# pocket register map
Vendor: litex
Registers are 32-bit, read-write, reset 0x0 unless marked. A register's access mark holds for its fields unless they carry their own. Offsets are from the block's base; [hi:lo] are bit positions; {n}, {i} and the like mark numbered series; 'fields as' and 'values as' point back to an identical list.

## APF_INPUT
Base 0xF0001000
0x00 CONT1_KEY — Controller 1 inputs. See docs.
0x04 CONT2_KEY — Controller 2 inputs. See docs.
0x08 CONT3_KEY — Controller 3 inputs. See docs.
0x0C CONT4_KEY — Controller 4 inputs. See docs.
{0xC+4i} CONT{i}_JOY (i=1..4) — Controller {i} joystick values. See docs.
{0x1C+4i} CONT{i}_TRIG (i=1..4) — Controller {i} trigger values. Values are binary on Pocket (`0 and 0xFFFF`), and analog on controllers with analog triggers. See docs.

## APF_INTERACT
Base 0xF0001800
0x00 INTERACT0 — Interact.json entry 0.
0x04 INTERACT_CHANGED0 — When 1, indicates the interact.json entry 0 has been updated.
  [0] interact_changed0
0x08 INTERACT1 — Interact.json entry 1.
0x0C INTERACT_CHANGED1 — When 1, indicates the interact.json entry 1 has been updated.
  [0] interact_changed1

## APF_VIDEO
Base 0xF0002000
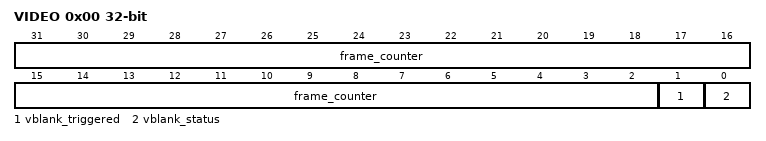
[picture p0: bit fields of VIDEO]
0x00 VIDEO
  [31:2] frame_counter — Counts the number of frames displayed since startup. Comparing this value to a previous value can be used to track frame changes. A frame change is considered to occur at the start of vblank.
  [1] vblank_triggered — Indicates when vblank occurs. Becomes 1 at vblank, and is set to 0 whenever read. If you read 1, vblank has started between your two reads.
  [0] vblank_status — 1 when in vblank, 0 otherwise.

## CTRL
Base 0xF0002800
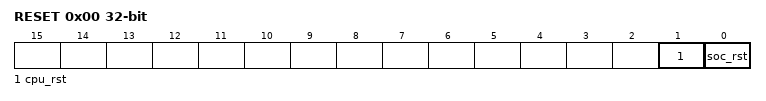
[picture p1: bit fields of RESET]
0x00 RESET
  [1] cpu_rst — Write `1` to this register to reset the CPU(s) of the SoC (Hold Reset)
  [0] soc_rst — Write `1` to this register to reset the full SoC (Pulse Reset)
0x04 SCRATCH reset 0x12345678 — Use this register as a scratch space to verify that software read/write accesses to the Wishbone/CSR bus are working correctly. The initial reset value of 0x1234578 can be used to verify endianness.
0x08 BUS_ERRORS — Total number of Wishbone bus errors (timeouts) since start.

## IDENTIFIER_MEM
Base 0xF0003000
0x00 IDENTIFIER_MEM — 8 x 47-bit memory
  [7:0] identifier_mem

## MAILBOX
Base 0xF0003800
0x00 GAME_MSG — Message word from game CPU to geometry CPU.
0x04 GAME_KICK
  [0] game_kick
0x08 GEOM_ACK
  [0] geom_ack
0x0C GEOM_MSG — Message word from geometry CPU to game CPU.
0x10 GEOM_KICK
  [0] geom_kick
0x14 GAME_ACK
  [0] game_ack
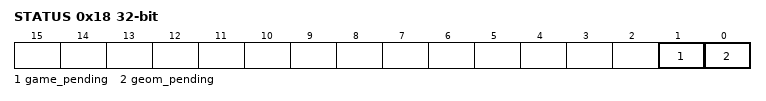
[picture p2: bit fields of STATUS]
0x18 STATUS
  [1] game_pending — Doorbell pending towards the game CPU.
  [0] geom_pending — Doorbell pending towards the geometry CPU.

## MRDP
Base 0xF0004000
0x00 CMD_DATA — Push one command word. Poll cmd_status.level first: a write to a full FIFO is lost (and counted in cmd_dropped).
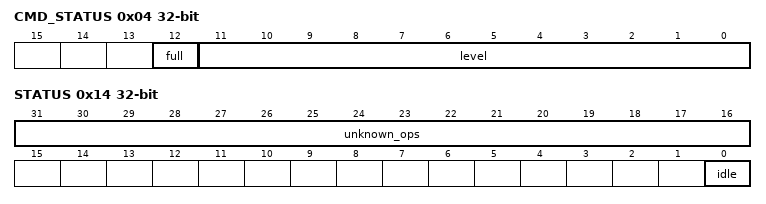
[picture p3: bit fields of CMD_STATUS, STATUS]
0x04 CMD_STATUS
  [12] full — Command FIFO full: a write now would be lost.
  [11:0] level — Command FIFO fill level.
0x08 CMD_DROPPED — Command words written while the FIFO was full (lost).
  [15:0] cmd_dropped
0x0C SYNC_COUNT — SYNC FULLs completed: every write before them is in DRAM.
0x10 LOAD_COUNT — LOAD TILEs completed (their staging memory is free again).
0x14 STATUS
  [31:16] unknown_ops — Unknown opcodes skipped.
  [0] idle — No command in progress, nothing queued, no write pending.

## SDRAM
Base 0xF0004800
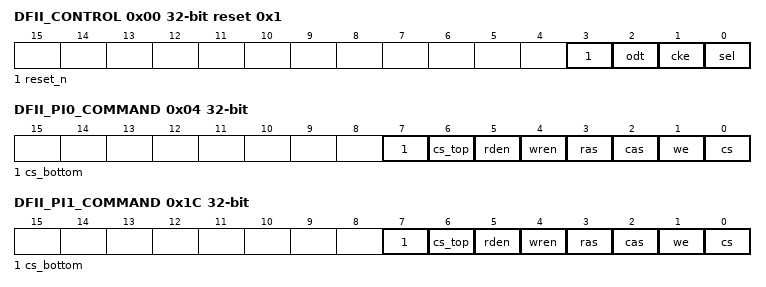
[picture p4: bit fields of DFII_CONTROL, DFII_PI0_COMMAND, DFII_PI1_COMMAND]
0x00 DFII_CONTROL reset 0x1 — Control DFI signals common to all phases
  [3] reset_n — DFI clock reset bus
  [2] odt — DFI on-die termination bus
  [1] cke — DFI clock enable bus
  [0] sel
0x04 DFII_PI0_COMMAND — Control DFI signals on a single phase
  [7] cs_bottom — DFI chip select bus for bottom half only
  [6] cs_top — DFI chip select bus for top half only
  [5] rden — DFI read data enable bus
  [4] wren — DFI write data enable bus
  [3] ras — DFI row address strobe bus
  [2] cas — DFI column address strobe bus
  [1] we — DFI write enable bus
  [0] cs — DFI chip select bus
0x08 DFII_PI0_COMMAND_ISSUE
  [0] dfii_pi0_command_issue
0x0C DFII_PI0_ADDRESS — DFI address bus
  [12:0] dfii_pi0_address
0x10 DFII_PI0_BADDRESS — DFI bank address bus
  [1:0] dfii_pi0_baddress
0x14 DFII_PI0_WRDATA — DFI write data bus
  [15:0] dfii_pi0_wrdata
0x18 DFII_PI0_RDDATA — DFI read data bus
  [15:0] dfii_pi0_rddata
0x1C DFII_PI1_COMMAND — Control DFI signals on a single phase
  fields as DFII_PI0_COMMAND
0x20 DFII_PI1_COMMAND_ISSUE
  [0] dfii_pi1_command_issue
0x24 DFII_PI1_ADDRESS — DFI address bus
  [12:0] dfii_pi1_address
0x28 DFII_PI1_BADDRESS — DFI bank address bus
  [1:0] dfii_pi1_baddress
0x2C DFII_PI1_WRDATA — DFI write data bus
  [15:0] dfii_pi1_wrdata
0x30 DFII_PI1_RDDATA — DFI read data bus
  [15:0] dfii_pi1_rddata

## TIMER0
Base 0xF0005000
0x00 LOAD — Load value when Timer is (re-)enabled. In One-Shot mode, the value written to this register specifies the Timer's duration in clock cycles.
0x04 RELOAD — Reload value when Timer reaches ``0``. In Periodic mode, the value written to this register specify the Timer's period in clock cycles.
0x08 EN — Enable flag of the Timer. Set this flag to ``1`` to enable/start the Timer. Set to ``0`` to disable the Timer.
  [0] en
0x0C UPDATE_VALUE — Update trigger for the current countdown value. A write to this register latches the current countdown value to ``value`` register.
  [0] update_value
0x10 VALUE — Latched countdown value. This value is updated by writing to ``update_value``.
0x14 EV_STATUS — This register contains the current raw level of the zero event trigger. Writes to this register have no effect.
  [0] zero — Level of the ``zero`` event
0x18 EV_PENDING — When a zero event occurs, the corresponding bit will be set in this register. To clear the Event, set the corresponding bit in this register.
  [0] zero — `1` if a `zero` event occurred. This Event is triggered on a **falling** edge.
0x1C EV_ENABLE — This register enables the corresponding zero events. Write a ``0`` to this register to disable individual events.
  [0] zero — Write a ``1`` to enable the ``zero`` Event
0x20 UPTIME_LATCH — Write a ``1`` to latch current Uptime cycles to ``uptime_cycles`` register.
  [0] uptime_latch
0x24 UPTIME_CYCLES1 — Bits 32-63 of `TIMER0_UPTIME_CYCLES`. Latched Uptime since power-up (in ``sys_clk`` cycles).
  [31:0] uptime_cycles
0x28 UPTIME_CYCLES0 — Bits 0-31 of `TIMER0_UPTIME_CYCLES`.
  [31:0] uptime_cycles

## UART
Base 0xF0005800
0x00 RXTX
  [7:0] rxtx
0x04 TXFULL — TX FIFO Full.
  [0] txfull
0x08 RXEMPTY — RX FIFO Empty.
  [0] rxempty
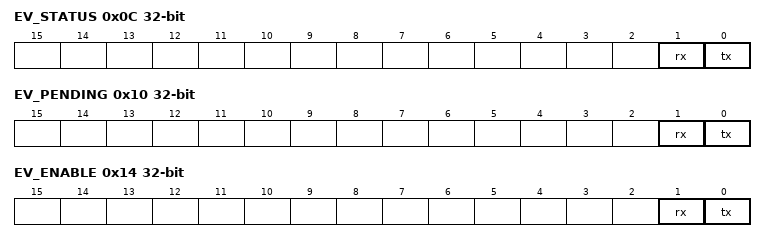
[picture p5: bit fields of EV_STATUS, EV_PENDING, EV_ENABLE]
0x0C EV_STATUS — This register contains the current raw level of the rx event trigger. Writes to this register have no effect.
  [1] rx — Level of the ``rx`` event
  [0] tx — Level of the ``tx`` event
0x10 EV_PENDING — When a rx event occurs, the corresponding bit will be set in this register. To clear the Event, set the corresponding bit in this register.
  [1] rx — `1` if a `rx` event occurred. This Event is triggered on a **falling** edge.
  [0] tx — `1` if a `tx` event occurred. This Event is triggered on a **falling** edge.
0x14 EV_ENABLE — This register enables the corresponding rx events. Write a ``0`` to this register to disable individual events.
  [1] rx — Write a ``1`` to enable the ``rx`` Event
  [0] tx — Write a ``1`` to enable the ``tx`` Event
0x18 TXEMPTY — TX FIFO Empty.
  [0] txempty
0x1C RXFULL — RX FIFO Full.
  [0] rxfull

## VIDEO_FRAMEBUFFER
Base 0xF0006000
0x00 DMA_BASE reset 0x40C00000
0x04 DMA_LENGTH reset 0x1F680
0x08 DMA_ENABLE
  [0] dma_enable
0x0C DMA_DONE
  [0] dma_done
0x10 DMA_LOOP reset 0x1
  [0] dma_loop
0x14 DMA_OFFSET

## VIDEO_FRAMEBUFFER_VTG
Base 0xF0006800
0x00 ENABLE reset 0x1
  [0] enable
0x04 MODE — 0: the default timings, 1: the second set (320 x 240). Write with enable = 0.
  [0] mode
